# STM32F303 register map
File version: 1.4
CPU: CM4 r1p0, little endian, no MPU, no FPU, 4 interrupt priority bits
Registers are 32-bit, read-write, reset 0x0 unless marked. A register's access mark holds for its fields unless they carry their own. Offsets are from the block's base; [hi:lo] are bit positions; lines under a group give offsets from that group; {n}, {i} and the like mark numbered series; 'fields as' and 'values as' point back to an identical list.

## CAN — Controller area network
Base 0x40006400
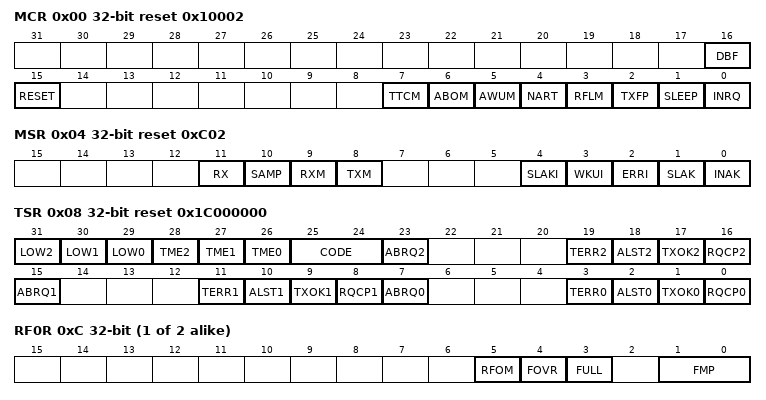
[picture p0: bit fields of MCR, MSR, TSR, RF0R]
0x00 MCR reset 0x10002 — master control register
  [16] DBF, [15] RESET, [7] TTCM, [6] ABOM, [5] AWUM, [4] NART, [3] RFLM, [2] TXFP, [1] SLEEP, [0] INRQ
0x04 MSR access per field reset 0xC02 — master status register
  [11] RX ro, [10] SAMP ro, [9] RXM ro, [8] TXM ro, [4] SLAKI rw, [3] WKUI rw, [2] ERRI rw, [1] SLAK ro, [0] INAK ro
0x08 TSR access per field reset 0x1C000000 — transmit status register
  [31] LOW2 ro — Lowest priority flag for mailbox 2
  [30] LOW1 ro — Lowest priority flag for mailbox 1
  [29] LOW0 ro — Lowest priority flag for mailbox 0
  [28] TME2 ro — Lowest priority flag for mailbox 2
  [27] TME1 ro — Lowest priority flag for mailbox 1
  [26] TME0 ro — Lowest priority flag for mailbox 0
  [25:24] CODE ro
  [23] ABRQ2 rw
  [19] TERR2 rw
  [18] ALST2 rw
  [17] TXOK2 rw
  [16] RQCP2 rw
  [15] ABRQ1 rw
  [11] TERR1 rw
  [10] ALST1 rw
  [9] TXOK1 rw
  [8] RQCP1 rw
  [7] ABRQ0 rw
  [3] TERR0 rw
  [2] ALST0 rw
  [1] TXOK0 rw
  [0] RQCP0 rw
{0xC+4i} RF{i}R (i=0..1) access per field — receive FIFO {i} register
  [5] RFOM rw — RFOM0
    on write: 1=Release (Set by software to release the output mailbox of the FIFO)
  [4] FOVR rw — FOVR0
    on read: 0=NoOverrun (No FIFO x overrun); 1=Overrun (FIFO x overrun) | on write: 1=Clear flag
  [3] FULL rw — FULL0
    on read: 0=NotFull (FIFO x is not full); 1=Full (FIFO x is full) | on write: 1=Clear flag
  [1:0] FMP ro — FMP0
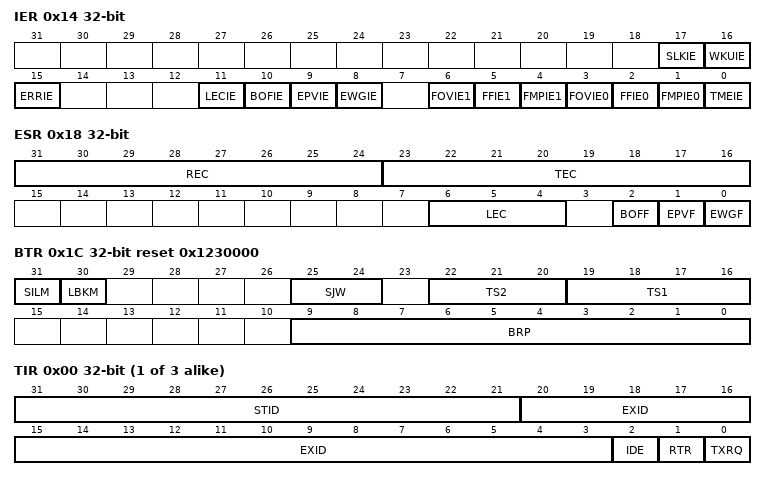
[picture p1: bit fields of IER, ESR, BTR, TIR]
0x14 IER — interrupt enable register
  [17] SLKIE
    0=Disabled (No interrupt when SLAKI bit is set); 1=Enabled (Interrupt generated when SLAKI bit is set)
  [16] WKUIE
    0=Disabled (No interrupt when WKUI is set); 1=Enabled (Interrupt generated when WKUI bit is set)
  [15] ERRIE
    0=Disabled (No interrupt will be generated when an error condition is pending in the CAN_ESR); 1=Enabled (An interrupt will be generation when an error condition is pending in the CAN_ESR)
  [11] LECIE
    0=Disabled (ERRI bit will not be set when the error code in LEC[2:0] is set by hardware on error detection); 1=Enabled (ERRI bit will be set when the error code in LEC[2:0] is set by hardware on error detection)
  [10] BOFIE
    0=Disabled (ERRI bit will not be set when BOFF is set); 1=Enabled (ERRI bit will be set when BOFF is set)
  [9] EPVIE
    0=Disabled (ERRI bit will not be set when EPVF is set); 1=Enabled (ERRI bit will be set when EPVF is set)
  [8] EWGIE
    0=Disabled (ERRI bit will not be set when EWGF is set); 1=Enabled (ERRI bit will be set when EWGF is set)
  [6] FOVIE1
    0=Disabled (No interrupt when FOVR is set); 1=Enabled (Interrupt generation when FOVR is set)
  [5] FFIE1
    0=Disabled (No interrupt when FULL bit is set); 1=Enabled (Interrupt generated when FULL bit is set)
  [4] FMPIE1
    0=Disabled (No interrupt generated when state of FMP[1:0] bits are not 00b); 1=Enabled (Interrupt generated when state of FMP[1:0] bits are not 00b)
  [3] FOVIE0
    0=Disabled (No interrupt when FOVR bit is set); 1=Enabled (Interrupt generated when FOVR bit is set)
  [2] FFIE0
    values as FFIE1
  [1] FMPIE0
    0=Disabled (No interrupt generated when state of FMP[1:0] bits are not 00); 1=Enabled (Interrupt generated when state of FMP[1:0] bits are not 00b)
  [0] TMEIE
    0=Disabled (No interrupt when RQCPx bit is set); 1=Enabled (Interrupt generated when RQCPx bit is set)
0x18 ESR access per field — error status register
  [31:24] REC ro
  [23:16] TEC ro
  [6:4] LEC rw
    0=NoError; 1=Stuff Error; 2=Form Error; 3=Ack (Acknowledgment Error); 4=Bit recessive Error; 5=Bit dominant Error; 6=Crc (CRC Error); 7=Custom (Set by software)
  [2] BOFF ro
  [1] EPVF ro
  [0] EWGF ro
0x1C BTR reset 0x1230000 — bit timing register
  [31] SILM
    0=Normal operation; 1=Silent Mode
  [30] LBKM
    0=Disabled (Loop Back Mode disabled); 1=Enabled (Loop Back Mode enabled)
  [25:24] SJW
  [22:20] TS2
  [19:16] TS1
  [9:0] BRP
{0x180+0x10*i} TX{i} (i=0..2) group — CAN Transmit cluster
  0x00 TIR — TX mailbox identifier register
    [31:21] STID
    [20:3] EXID
    [2] IDE
      0=Standard identifier; 1=Extended identifier
    [1] RTR
      0=Data frame; 1=Remote frame
    [0] TXRQ
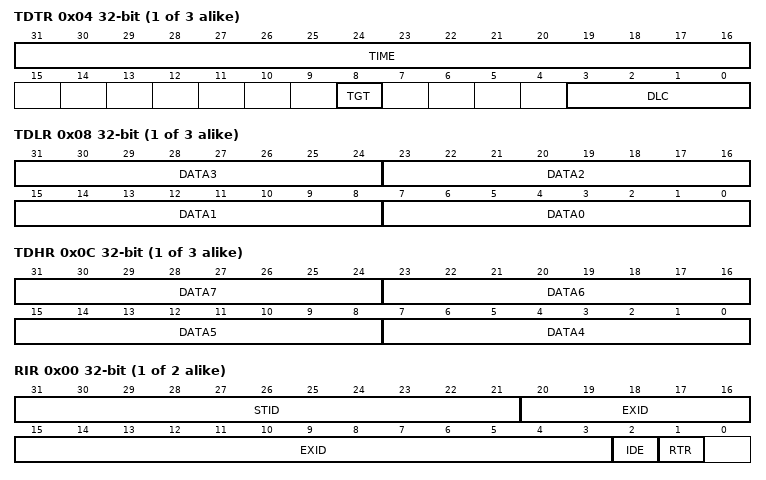
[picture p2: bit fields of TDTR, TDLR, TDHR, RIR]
  0x04 TDTR — mailbox data length control and time stamp register
    [31:16] TIME, [8] TGT, [3:0] DLC range 0..8
  0x08 TDLR — mailbox data low register
    [8n+7:8n] DATA{n} (n=0..3)
  0x0C TDHR — mailbox data high register
    [8n-25:8n-32] DATA{n} (n=4..7)
{0x1B0+0x10*i} RX{i} (i=0..1) group — CAN Receive cluster
  0x00 RIR ro — receive FIFO mailbox identifier register
    [31:21] STID
    [20:3] EXID
    [2] IDE
      0=Standard identifier; 1=Extended identifier
    [1] RTR
      0=Data frame; 1=Remote frame
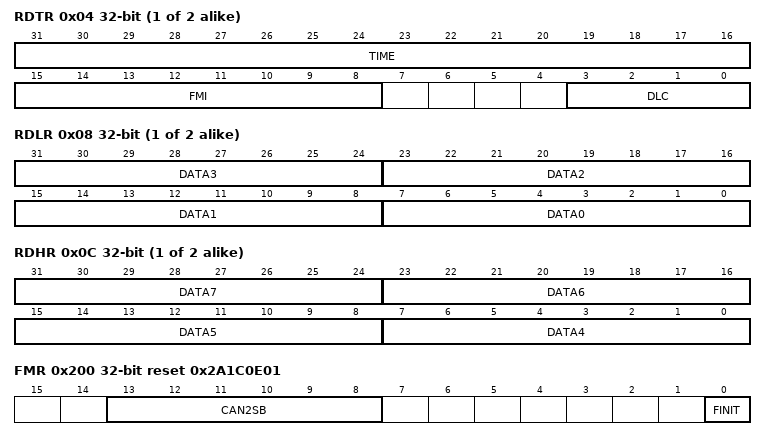
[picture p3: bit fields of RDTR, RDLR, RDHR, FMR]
  0x04 RDTR ro — receive FIFO mailbox data length control and time stamp register
    [31:16] TIME, [15:8] FMI, [3:0] DLC range 0..8
  0x08 RDLR ro — receive FIFO mailbox data low register
    [8n+7:8n] DATA{n} (n=0..3)
  0x0C RDHR ro — receive FIFO mailbox data high register
    [8n-25:8n-32] DATA{n} (n=4..7)
0x200 FMR reset 0x2A1C0E01 — filter master register
  [13:8] CAN2SB — CAN2 start bank
  [0] FINIT — Filter init mode
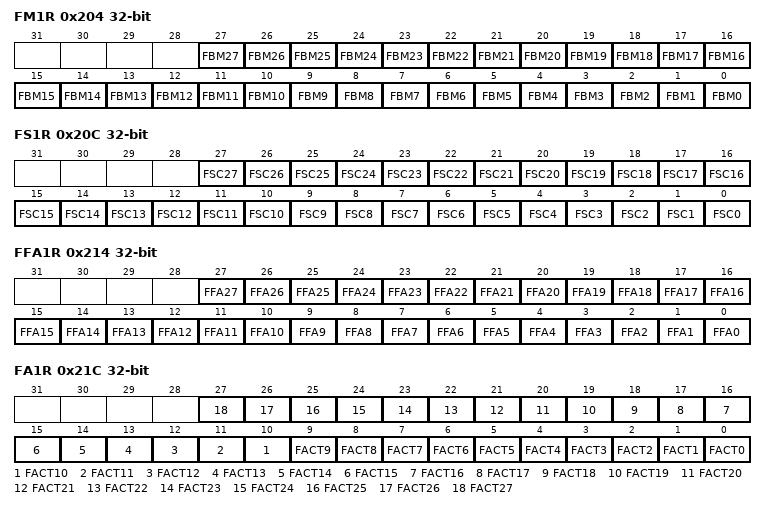
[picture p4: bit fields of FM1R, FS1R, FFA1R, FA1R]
0x204 FM1R — filter mode register
  [n] FBM{n} (n=0..27) — Filter mode
0x20C FS1R — filter scale register
  [n] FSC{n} (n=0..27) — Filter scale configuration
0x214 FFA1R — filter FIFO assignment register
  [n] FFA{n} (n=0..27) — Filter FIFO assignment for filter {n}
0x21C FA1R — CAN filter activation register
  [n] FACT{n} (n=0..27) — Filter active
{0x240+8i} FB{i} (i=0..27) group — CAN Filter Bank cluster
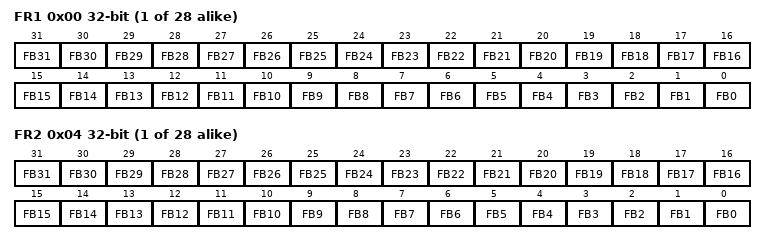
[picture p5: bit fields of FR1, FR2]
  0x00 FR1 — Filter bank 0 register 1
    [n] FB{n} (n=0..31) — Filter bits
  0x04 FR2 — Filter bank 0 register 2
    [n] FB{n} (n=0..31) — Filter bits
